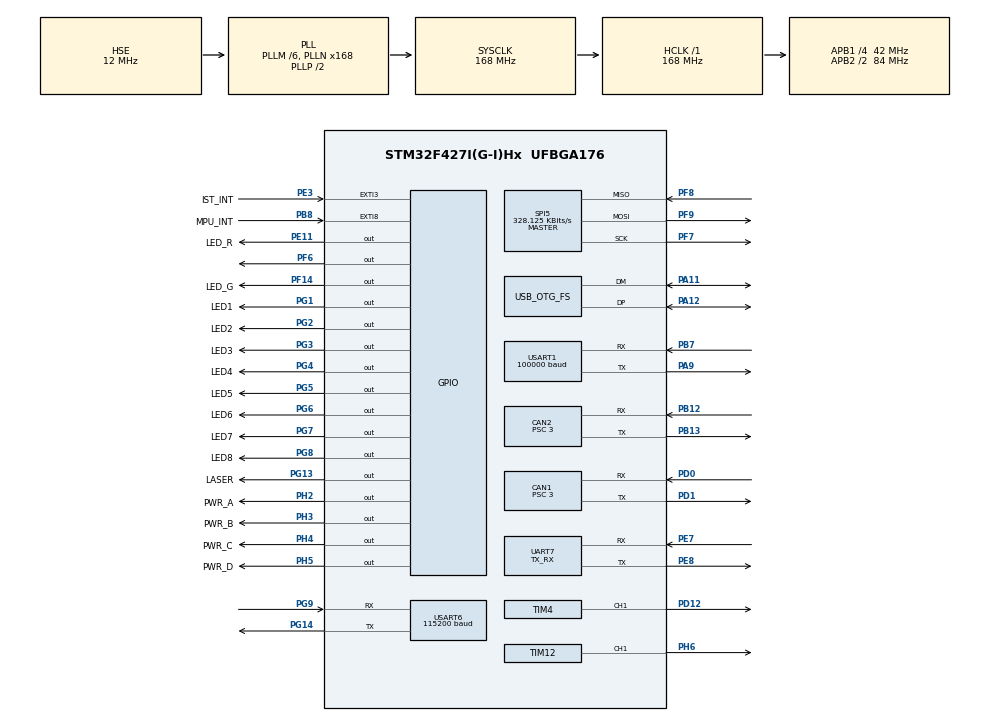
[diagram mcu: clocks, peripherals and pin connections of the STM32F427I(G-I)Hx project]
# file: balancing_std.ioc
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CAN1.ABOM=DISABLE
CAN1.BS1=CAN_BS1_9TQ
CAN1.BS2=CAN_BS2_4TQ
CAN1.CalculateBaudRate=1000000
CAN1.CalculateTimeBit=1000
CAN1.CalculateTimeQuantum=71.42857142857143
CAN1.NART=DISABLE
CAN1.Prescaler=3
CAN2.BS1=CAN_BS1_9TQ
CAN2.BS2=CAN_BS2_4TQ
CAN2.CalculateBaudRate=1000000
CAN2.CalculateTimeBit=1000
CAN2.CalculateTimeQuantum=71.42857142857143
CAN2.Prescaler=3
Dma.Request0=USART1_RX
Dma.Request1=USART6_RX
Dma.Request2=UART7_RX
Dma.Request3=SPI5_RX
Dma.Request4=SPI5_TX
Dma.SPI5_RX.3.Direction=DMA_PERIPH_TO_MEMORY
Dma.SPI5_RX.3.FIFOMode=DMA_FIFOMODE_ENABLE
Dma.SPI5_RX.3.FIFOThreshold=DMA_FIFO_THRESHOLD_FULL
Dma.SPI5_RX.3.Instance=DMA2_Stream3
Dma.SPI5_RX.3.MemBurst=DMA_MBURST_SINGLE
Dma.SPI5_RX.3.MemDataAlignment=DMA_MDATAALIGN_BYTE
Dma.SPI5_RX.3.MemInc=DMA_MINC_ENABLE
Dma.SPI5_RX.3.Mode=DMA_NORMAL
Dma.SPI5_RX.3.PeriphBurst=DMA_PBURST_SINGLE
Dma.SPI5_RX.3.PeriphDataAlignment=DMA_PDATAALIGN_BYTE
Dma.SPI5_RX.3.PeriphInc=DMA_PINC_DISABLE
Dma.SPI5_RX.3.Priority=DMA_PRIORITY_VERY_HIGH
Dma.SPI5_TX.4.Direction=DMA_MEMORY_TO_PERIPH
Dma.SPI5_TX.4.FIFOMode=DMA_FIFOMODE_DISABLE
Dma.SPI5_TX.4.Instance=DMA2_Stream4
Dma.SPI5_TX.4.MemDataAlignment=DMA_MDATAALIGN_BYTE
Dma.SPI5_TX.4.MemInc=DMA_MINC_ENABLE
Dma.SPI5_TX.4.Mode=DMA_NORMAL
Dma.SPI5_TX.4.PeriphDataAlignment=DMA_PDATAALIGN_BYTE
Dma.SPI5_TX.4.PeriphInc=DMA_PINC_DISABLE
Dma.SPI5_TX.4.Priority=DMA_PRIORITY_VERY_HIGH
Dma.UART7_RX.2.Direction=DMA_PERIPH_TO_MEMORY
Dma.UART7_RX.2.FIFOMode=DMA_FIFOMODE_DISABLE
Dma.UART7_RX.2.Instance=DMA1_Stream3
Dma.UART7_RX.2.MemDataAlignment=DMA_MDATAALIGN_BYTE
Dma.UART7_RX.2.MemInc=DMA_MINC_ENABLE
Dma.UART7_RX.2.Mode=DMA_CIRCULAR
Dma.UART7_RX.2.PeriphDataAlignment=DMA_PDATAALIGN_BYTE
Dma.UART7_RX.2.PeriphInc=DMA_PINC_DISABLE
Dma.UART7_RX.2.Priority=DMA_PRIORITY_LOW
Dma.USART1_RX.0.Direction=DMA_PERIPH_TO_MEMORY
Dma.USART1_RX.0.FIFOMode=DMA_FIFOMODE_DISABLE
Dma.USART1_RX.0.Instance=DMA2_Stream2
Dma.USART1_RX.0.MemDataAlignment=DMA_MDATAALIGN_BYTE
Dma.USART1_RX.0.MemInc=DMA_MINC_ENABLE
Dma.USART1_RX.0.Mode=DMA_CIRCULAR
Dma.USART1_RX.0.PeriphDataAlignment=DMA_PDATAALIGN_BYTE
Dma.USART1_RX.0.PeriphInc=DMA_PINC_DISABLE
Dma.USART1_RX.0.Priority=DMA_PRIORITY_LOW
Dma.USART6_RX.1.Direction=DMA_PERIPH_TO_MEMORY
Dma.USART6_RX.1.FIFOMode=DMA_FIFOMODE_DISABLE
Dma.USART6_RX.1.Instance=DMA2_Stream1
Dma.USART6_RX.1.MemDataAlignment=DMA_MDATAALIGN_BYTE
Dma.USART6_RX.1.MemInc=DMA_MINC_ENABLE
Dma.USART6_RX.1.Mode=DMA_CIRCULAR
Dma.USART6_RX.1.PeriphDataAlignment=DMA_PDATAALIGN_BYTE
Dma.USART6_RX.1.PeriphInc=DMA_PINC_DISABLE
Dma.USART6_RX.1.Priority=DMA_PRIORITY_LOW
FATFS._FS_NORTC=1
FATFS._NORTC_MDAY=3
FATFS._NORTC_MON=8
FATFS._NORTC_YEAR=2021
FREERTOS.INCLUDE_vTaskDelayUntil=1
FREERTOS.INCLUDE_xEventGroupSetBitFromISR=1
FREERTOS.INCLUDE_xTaskGetHandle=1
FREERTOS.INCLUDE_xTimerPendFunctionCall=1
FREERTOS.Tasks01=defaultTask,0,128,StartDefaultTask,Default,NULL,Dynamic,NULL,NULL
FREERTOS.configGENERATE_RUN_TIME_STATS=1
FREERTOS.configUSE_CO_ROUTINES=1
FREERTOS.configUSE_NEWLIB_REENTRANT=1
FREERTOS.configUSE_TIMERS=1
Mcu.Family=STM32F4
Mcu.Name=STM32F427I(G-I)Hx
Mcu.Package=UFBGA176
NVIC.CAN1_RX0_IRQn=true\:5\:0\:true\:false\:true\:true\:true\:true\:true
NVIC.CAN2_RX0_IRQn=true\:5\:0\:false\:false\:true\:true\:true\:true\:true
NVIC.CAN2_RX1_IRQn=true\:5\:0\:false\:false\:true\:true\:true\:true\:true
NVIC.DMA1_Stream3_IRQn=true\:5\:0\:false\:false\:true\:true\:false\:true\:true
NVIC.DMA2_Stream1_IRQn=true\:5\:0\:true\:false\:true\:false\:false\:true\:true
NVIC.DMA2_Stream2_IRQn=true\:5\:0\:true\:false\:true\:false\:false\:true\:true
NVIC.DMA2_Stream3_IRQn=true\:5\:0\:false\:false\:true\:true\:false\:true\:true
NVIC.DMA2_Stream4_IRQn=true\:5\:0\:false\:false\:true\:true\:false\:true\:true
NVIC.EXTI3_IRQn=true\:5\:0\:true\:false\:true\:true\:true\:true\:true
NVIC.EXTI9_5_IRQn=true\:5\:0\:true\:false\:true\:true\:true\:true\:true
NVIC.OTG_FS_IRQn=true\:5\:0\:false\:false\:true\:true\:false\:true\:true
NVIC.PriorityGroup=NVIC_PRIORITYGROUP_4
NVIC.SPI5_IRQn=true\:5\:0\:true\:false\:true\:false\:true\:true\:true
NVIC.TIM1_UP_TIM10_IRQn=true\:5\:0\:false\:false\:true\:true\:true\:true\:true
NVIC.TIM3_IRQn=true\:0\:0\:false\:false\:true\:false\:false\:true\:true
NVIC.TimeBase=TIM3_IRQn
NVIC.TimeBaseIP=TIM3
NVIC.UART7_IRQn=true\:5\:0\:true\:false\:true\:true\:true\:true\:true
NVIC.USART1_IRQn=true\:5\:0\:false\:false\:true\:true\:true\:true\:true
NVIC.USART6_IRQn=true\:5\:0\:true\:false\:true\:true\:true\:true\:true
PA11.Mode=Device_Only
PA11.Signal=USB_OTG_FS_DM
PA12.Mode=Device_Only
PA12.Signal=USB_OTG_FS_DP
PA13.Mode=Serial_Wire
PA13.Signal=SYS_JTMS-SWDIO
PA14.Mode=Serial_Wire
PA14.Signal=SYS_JTCK-SWCLK
PA7.Signal=SPI1_MOSI
PA9.Mode=Asynchronous
PA9.Signal=USART1_TX
PB12.Mode=CAN_Activate
PB12.Signal=CAN2_RX
PB13.Mode=CAN_Activate
PB13.Signal=CAN2_TX
PB7.Mode=Asynchronous
PB7.Signal=USART1_RX
PB8.GPIO_Label=MPU_INT
PB8.GPIO_PuPd=GPIO_PULLDOWN
PB8.Signal=GPXTI8
PD0.Mode=CAN_Activate
PD0.Signal=CAN1_RX
PD1.Mode=CAN_Activate
PD1.Signal=CAN1_TX
PD12.Signal=S_TIM4_CH1
PE11.GPIO_Label=LED_R
PE11.Signal=GPIO_Output
PE3.GPIO_Label=IST_INT
PE3.GPIO_PuPd=GPIO_PULLDOWN
PE3.Signal=GPXTI3
PE7.Mode=Asynchronous
PE7.Signal=UART7_RX
PE8.Mode=Asynchronous
PE8.Signal=UART7_TX
PF14.GPIO_Label=LED_G
PF14.Signal=GPIO_Output
PF6.GPIO_PuPd=GPIO_PULLDOWN
PF6.GPIO_Speed=GPIO_SPEED_FREQ_MEDIUM
PF6.PinState=GPIO_PIN_SET
PF6.Signal=GPIO_Output
PF7.Mode=Full_Duplex_Master
PF7.Signal=SPI5_SCK
PF8.Mode=Full_Duplex_Master
PF8.Signal=SPI5_MISO
PF9.Mode=Full_Duplex_Master
PF9.Signal=SPI5_MOSI
PG1.GPIO_Label=LED1
PG1.GPIO_ModeDefaultOutputPP=GPIO_MODE_OUTPUT_PP
PG1.GPIO_Speed=GPIO_SPEED_FREQ_VERY_HIGH
PG1.PinState=GPIO_PIN_SET
PG1.Signal=GPIO_Output
PG13.GPIO_Label=LASER
PG13.GPIO_ModeDefaultOutputPP=GPIO_MODE_OUTPUT_PP
PG13.PinState=GPIO_PIN_RESET
PG13.Signal=GPIO_Output
PG14.Mode=Asynchronous
PG14.Signal=USART6_TX
PG2.GPIO_Label=LED2
PG2.GPIO_ModeDefaultOutputPP=GPIO_MODE_OUTPUT_PP
PG2.GPIO_Speed=GPIO_SPEED_FREQ_VERY_HIGH
PG2.PinState=GPIO_PIN_SET
PG2.Signal=GPIO_Output
PG3.GPIO_Label=LED3
PG3.GPIO_ModeDefaultOutputPP=GPIO_MODE_OUTPUT_PP
PG3.GPIO_Speed=GPIO_SPEED_FREQ_VERY_HIGH
PG3.PinState=GPIO_PIN_SET
PG3.Signal=GPIO_Output
PG4.GPIO_Label=LED4
PG4.GPIO_ModeDefaultOutputPP=GPIO_MODE_OUTPUT_PP
PG4.GPIO_Speed=GPIO_SPEED_FREQ_VERY_HIGH
PG4.PinState=GPIO_PIN_SET
PG4.Signal=GPIO_Output
PG5.GPIO_Label=LED5
PG5.GPIO_ModeDefaultOutputPP=GPIO_MODE_OUTPUT_PP
PG5.GPIO_Speed=GPIO_SPEED_FREQ_VERY_HIGH
PG5.PinState=GPIO_PIN_SET
PG5.Signal=GPIO_Output
PG6.GPIO_Label=LED6
PG6.GPIO_ModeDefaultOutputPP=GPIO_MODE_OUTPUT_PP
PG6.GPIO_Speed=GPIO_SPEED_FREQ_VERY_HIGH
PG6.PinState=GPIO_PIN_SET
PG6.Signal=GPIO_Output
PG7.GPIO_Label=LED7
PG7.GPIO_ModeDefaultOutputPP=GPIO_MODE_OUTPUT_PP
PG7.GPIO_Speed=GPIO_SPEED_FREQ_VERY_HIGH
PG7.PinState=GPIO_PIN_SET
PG7.Signal=GPIO_Output
PG8.GPIO_Label=LED8
PG8.GPIO_ModeDefaultOutputPP=GPIO_MODE_OUTPUT_PP
PG8.GPIO_Speed=GPIO_SPEED_FREQ_VERY_HIGH
PG8.PinState=GPIO_PIN_SET
PG8.Signal=GPIO_Output
PG9.Mode=Asynchronous
PG9.Signal=USART6_RX
PH0/OSC_IN.Mode=HSE-External-Oscillator
PH0/OSC_IN.Signal=RCC_OSC_IN
PH1/OSC_OUT.Mode=HSE-External-Oscillator
PH1/OSC_OUT.Signal=RCC_OSC_OUT
PH2.GPIO_Label=PWR_A
PH2.GPIO_PuPd=GPIO_PULLUP
PH2.PinState=GPIO_PIN_SET
PH2.Signal=GPIO_Output
PH3.GPIO_Label=PWR_B
PH3.GPIO_PuPd=GPIO_PULLUP
PH3.PinState=GPIO_PIN_SET
PH3.Signal=GPIO_Output
PH4.GPIO_Label=PWR_C
PH4.GPIO_PuPd=GPIO_PULLUP
PH4.PinState=GPIO_PIN_SET
PH4.Signal=GPIO_Output
PH5.GPIO_Label=PWR_D
PH5.GPIO_PuPd=GPIO_PULLUP
PH5.PinState=GPIO_PIN_SET
PH5.Signal=GPIO_Output
PH6.Signal=S_TIM12_CH1
ProjectManager.HeapSize=0x200
ProjectManager.StackSize=0x400
ProjectManager.TargetToolchain=STM32CubeIDE
RCC.48MHZClocksFreq_Value=48000000
RCC.AHBFreq_Value=168000000
RCC.APB1CLKDivider=RCC_HCLK_DIV4
RCC.APB1Freq_Value=42000000
RCC.APB1TimFreq_Value=84000000
RCC.APB2CLKDivider=RCC_HCLK_DIV2
RCC.APB2Freq_Value=84000000
RCC.APB2TimFreq_Value=168000000
RCC.CortexFreq_Value=168000000
RCC.HCLKFreq_Value=168000000
RCC.HSE_VALUE=12000000
RCC.HSI_VALUE=16000000
RCC.LSE_VALUE=32768
RCC.PLLM=6
RCC.PLLN=168
RCC.PLLQ=7
RCC.SYSCLKFreq_VALUE=168000000
RCC.SYSCLKSource=RCC_SYSCLKSOURCE_PLLCLK
RCC.VCOOutputFreq_Value=336000000
SH.S_TIM12_CH1.0=TIM12_CH1,PWM Generation1 CH1
SH.S_TIM4_CH1.0=TIM4_CH1,PWM Generation1 CH1
SPI5.BaudRatePrescaler=SPI_BAUDRATEPRESCALER_256
SPI5.CLKPhase=SPI_PHASE_2EDGE
SPI5.CLKPolarity=SPI_POLARITY_HIGH
SPI5.CalculateBaudRate=328.125 KBits/s
SPI5.Direction=SPI_DIRECTION_2LINES
SPI5.FirstBit=SPI_FIRSTBIT_MSB
SPI5.Mode=SPI_MODE_MASTER
SPI5.VirtualType=VM_MASTER
TIM1.Channel-Output\ Compare1\ No\ Output=TIM_CHANNEL_1
TIM1.Period=1
TIM1.Prescaler=168-1
TIM12.Channel-PWM\ Generation1\ CH1=TIM_CHANNEL_1
TIM12.Period=1000
TIM12.Prescaler=84
TIM4.Channel-PWM\ Generation1\ CH1=TIM_CHANNEL_1
TIM4.Period=1000
TIM4.Prescaler=84
TIM5.Channel-PWM\ Generation1\ No\ Output=TIM_CHANNEL_1
TIM8.Channel-Output\ Compare1\ No\ Output=TIM_CHANNEL_1
UART7.Mode=MODE_TX_RX
UART7.VirtualMode=Asynchronous
USART1.BaudRate=100000
USART1.Mode=MODE_RX
USART1.Parity=PARITY_EVEN
USART1.VirtualMode=VM_ASYNC
USART1.WordLength=WORDLENGTH_9B
USART6.BaudRate=115200
USART6.Mode=MODE_RX
USART6.VirtualMode=VM_ASYNC
USB_DEVICE.CLASS_NAME_FS=CDC
USB_DEVICE.VirtualMode-CDC_FS=Cdc
USB_DEVICE.VirtualModeFS=Cdc_FS
USB_OTG_FS.VirtualMode=Device_Only
VP_FATFS_VS_Generic.Mode=User_defined
VP_FREERTOS_VS_CMSIS_V1.Mode=CMSIS_V1
VP_SYS_VS_tim3.Mode=TIM3
VP_TIM12_VS_ClockSourceINT.Mode=Internal
VP_TIM1_VS_no_output1.Mode=Output Compare1 No Output
VP_TIM5_VS_no_output1.Mode=PWM Generation1 No Output
VP_TIM8_VS_no_output1.Mode=Output Compare1 No Output
VP_USB_DEVICE_VS_USB_DEVICE_CDC_FS.Mode=CDC_FS
board=custom

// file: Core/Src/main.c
/* USER CODE BEGIN Header */
/**
  ******************************************************************************
  * @file           : main.c
  * @brief          : Main program body
  ******************************************************************************
  * @attention
  *
  * <h2><center>&copy; Copyright (c) 2021 STMicroelectronics.
  * All rights reserved.</center></h2>
  *
  * This software component is licensed by ST under Ultimate Liberty license
  * SLA0044, the "License"; You may not use this file except in compliance with
  * the License. You may obtain a copy of the License at:
  *                             www.st.com/SLA0044
  *
  ******************************************************************************
  */
/* USER CODE END Header */
#include "main.h"
#include "cmsis_os.h"
#include "can.h"
#include "dma.h"
#include "fatfs.h"
#include "spi.h"
#include "tim.h"
#include "usart.h"
#include "usb_device.h"
#include "gpio.h"

/* USER CODE BEGIN Includes */
#include "board_lib.h"
#include "startup_task.h"
/* USER CODE END Includes */

void SystemClock_Config(void);
void MX_FREERTOS_Init(void);

int main(void)
{

  /* MCU Configuration--------------------------------------------------------*/

  /* Reset of all peripherals, Initializes the Flash interface and the Systick. */
  HAL_Init();

  /* Configure the system clock */
  SystemClock_Config();

  /* Initialize all configured peripherals */
  MX_GPIO_Init();
  MX_DMA_Init();
  MX_USART1_UART_Init();
  MX_CAN1_Init();
  MX_USART6_UART_Init();
  MX_SPI5_Init();
  MX_TIM12_Init();
  MX_CAN2_Init();
  MX_TIM4_Init();
  MX_UART7_Init();
  MX_FATFS_Init();
  MX_TIM5_Init();
  MX_TIM8_Init();
  MX_TIM1_Init();
  /* USER CODE BEGIN 2 */

  startup_task();
  /* USER CODE END 2 */

  /* Call init function for freertos objects (in freertos.c) */
  MX_FREERTOS_Init();

  /* Start scheduler */
  osKernelStart();

  /* We should never get here as control is now taken by the scheduler */
  /* Infinite loop */
  while (1)
  {

  }
}

void SystemClock_Config(void)
{
  RCC_OscInitTypeDef RCC_OscInitStruct = {0};
  RCC_ClkInitTypeDef RCC_ClkInitStruct = {0};

  /** Configure the main internal regulator output voltage
  */
  __HAL_RCC_PWR_CLK_ENABLE();
  __HAL_PWR_VOLTAGESCALING_CONFIG(PWR_REGULATOR_VOLTAGE_SCALE1);

  /** Initializes the RCC Oscillators according to the specified parameters
  * in the RCC_OscInitTypeDef structure.
  */
  RCC_OscInitStruct.OscillatorType = RCC_OSCILLATORTYPE_HSE;
  RCC_OscInitStruct.HSEState = RCC_HSE_ON;
  RCC_OscInitStruct.PLL.PLLState = RCC_PLL_ON;
  RCC_OscInitStruct.PLL.PLLSource = RCC_PLLSOURCE_HSE;
  RCC_OscInitStruct.PLL.PLLM = 6;
  RCC_OscInitStruct.PLL.PLLN = 168;
  RCC_OscInitStruct.PLL.PLLP = RCC_PLLP_DIV2;
  RCC_OscInitStruct.PLL.PLLQ = 7;
  if (HAL_RCC_OscConfig(&RCC_OscInitStruct) != HAL_OK)
  {
    Error_Handler();
  }

  /** Initializes the CPU, AHB and APB buses clocks
  */
  RCC_ClkInitStruct.ClockType = RCC_CLOCKTYPE_HCLK|RCC_CLOCKTYPE_SYSCLK
                              |RCC_CLOCKTYPE_PCLK1|RCC_CLOCKTYPE_PCLK2;
  RCC_ClkInitStruct.SYSCLKSource = RCC_SYSCLKSOURCE_PLLCLK;
  RCC_ClkInitStruct.AHBCLKDivider = RCC_SYSCLK_DIV1;
  RCC_ClkInitStruct.APB1CLKDivider = RCC_HCLK_DIV4;
  RCC_ClkInitStruct.APB2CLKDivider = RCC_HCLK_DIV2;

  if (HAL_RCC_ClockConfig(&RCC_ClkInitStruct, FLASH_LATENCY_5) != HAL_OK)
  {
    Error_Handler();
  }
}

void HAL_TIM_PeriodElapsedCallback(TIM_HandleTypeDef *htim)
{
  if (htim->Instance == TIM3) {
    HAL_IncTick();
  }
}

void Error_Handler(void)
{
  __disable_irq();
  while (1)
  {
  }
}
